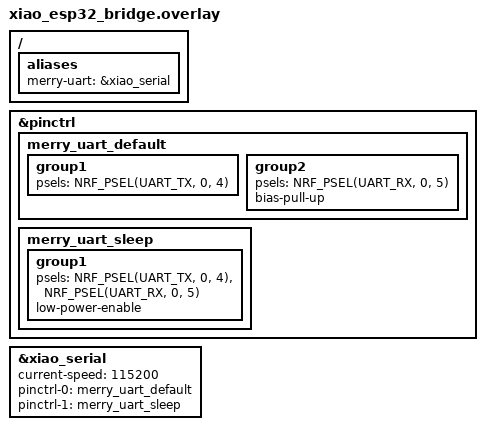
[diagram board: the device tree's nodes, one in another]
/* SPDX-License-Identifier: MIT */

#include <zephyr/dt-bindings/pinctrl/nrf-pinctrl.h>

/ {
    aliases {
        merry-uart = &xiao_serial;
    };
};

&pinctrl {
    merry_uart_default: merry_uart_default {
        group1 {
            psels = <NRF_PSEL(UART_TX, 0, 4)>; /* XIAO D4 */
        };
        group2 {
            psels = <NRF_PSEL(UART_RX, 0, 5)>; /* XIAO D5 */
            bias-pull-up;
        };
    };

    merry_uart_sleep: merry_uart_sleep {
        group1 {
            psels = <NRF_PSEL(UART_TX, 0, 4)>,
                    <NRF_PSEL(UART_RX, 0, 5)>;
            low-power-enable;
        };
    };
};

&xiao_serial {
    status = "okay";
    current-speed = <115200>;
    pinctrl-0 = <&merry_uart_default>;
    pinctrl-1 = <&merry_uart_sleep>;
    pinctrl-names = "default", "sleep";
};
